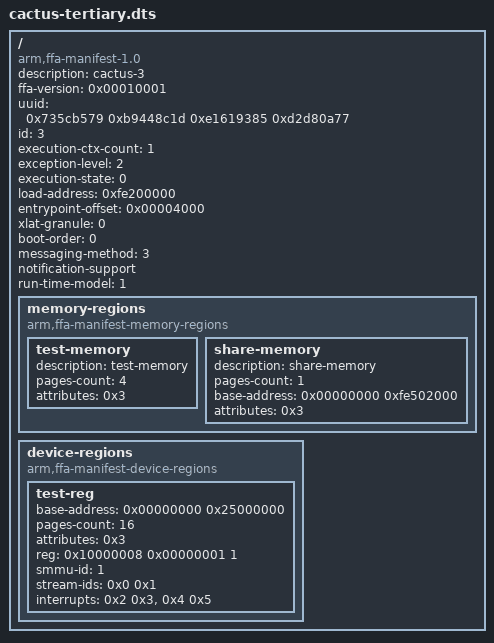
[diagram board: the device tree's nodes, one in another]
/*
 * Copyright (c) 2020-2021, Arm Limited. All rights reserved.
 *
 * SPDX-License-Identifier: BSD-3-Clause
 *
 * This file is a Partition Manifest (PM) for a minimal Secure Partition (SP)
 * that has additional optional properties defined.
 *
 */

/dts-v1/;

/ {
	compatible = "arm,ffa-manifest-1.0";

	/* Properties */
	description = "cactus-3";
	ffa-version = <0x00010001>; /* 31:16 - Major, 15:0 - Minor */
	uuid = <0x735cb579 0xb9448c1d 0xe1619385 0xd2d80a77>;
	id = <3>;
	execution-ctx-count = <1>;
	exception-level = <2>; /* S-EL1 */
	execution-state = <0>; /* AARCH64 */
	load-address = <0xfe200000>;
	entrypoint-offset = <0x00004000>;
	xlat-granule = <0>; /* 4KiB */
	boot-order = <0>;
	messaging-method = <3>; /* Direct messaging only */
	notification-support; /* Support receipt of notifications. */
	run-time-model = <1>; /* Run to completion */

	memory-regions {
		compatible = "arm,ffa-manifest-memory-regions";

		/* Without optional base-address */
		test-memory {
			description = "test-memory";
			pages-count = <4>;
			attributes = <0x3>; /* read-write */
		};

		/* Memory to be shared in memory sharing tests. */
		share-memory {
			description = "share-memory";
			pages-count = <1>;
			base-address =<0x00000000 0xfe502000>;
			attributes = <0x3>; /* read-write */
		};
	};

	device-regions {
		compatible = "arm,ffa-manifest-device-regions";

		test-reg {
			/* Dummy values */
			base-address = <0x00000000 0x25000000>;
			pages-count = <16>;
			attributes = <0x3>; /* read-write */
			reg = <0x10000008 0x00000001 1>;
			smmu-id = <1>;
			stream-ids = <0x0 0x1>;
			interrupts = <0x2 0x3>,
					<0x4 0x5>;
		};
	};

};
